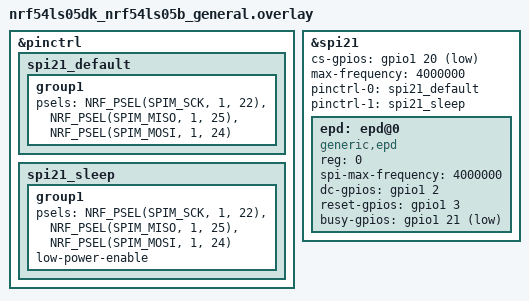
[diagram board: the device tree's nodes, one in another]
/*
 * Copyright (c) 2026 Nordic Semiconductor ASA
 *
 * SPDX-License-Identifier: Apache-2.0
 */

 &pinctrl {
	spi21_default: spi21_default {
		group1 {
			// nordic,drive-mode = <NRF_DRIVE_H0H1>;
			psels = <NRF_PSEL(SPIM_SCK, 1, 22)>,
			        <NRF_PSEL(SPIM_MISO, 1, 25)>,
			        <NRF_PSEL(SPIM_MOSI, 1, 24)>;
		};
	};

	spi21_sleep: spi21_sleep {
		group1 {
			psels = <NRF_PSEL(SPIM_SCK, 1, 22)>,
			        <NRF_PSEL(SPIM_MISO, 1, 25)>,
			        <NRF_PSEL(SPIM_MOSI, 1, 24)>;
			low-power-enable;
		};
	};

};

 &spi21 {
	cs-gpios = <&gpio1 20 GPIO_ACTIVE_LOW>;
	status = "okay";
	max-frequency = <4000000>;
	pinctrl-0 = <&spi21_default>;
	pinctrl-1 = <&spi21_sleep>;
	pinctrl-names = "default", "sleep";

	epd: epd@0 {
		compatible = "generic,epd";
		reg = <0>;
		status = "okay";
		spi-max-frequency = <4000000>;
		dc-gpios = <&gpio1 2 GPIO_ACTIVE_HIGH>;
		reset-gpios = <&gpio1 3 GPIO_ACTIVE_HIGH>;
		busy-gpios = <&gpio1 21 GPIO_ACTIVE_LOW>;
	};
 };
